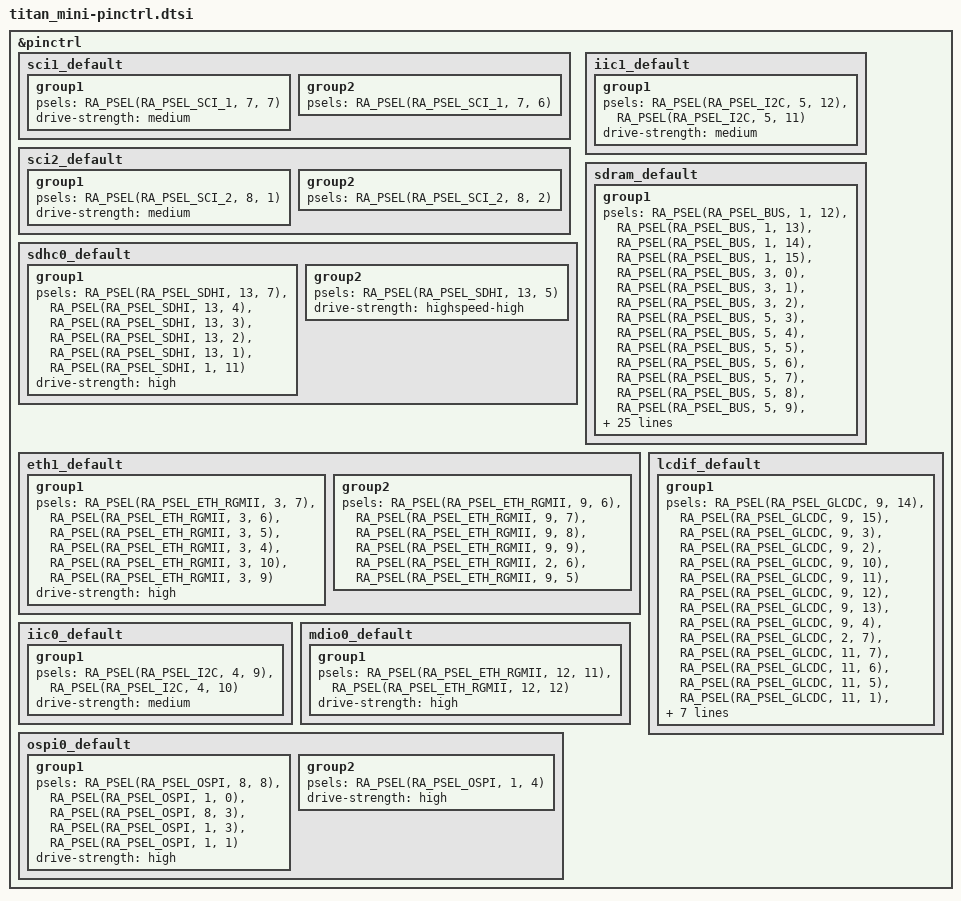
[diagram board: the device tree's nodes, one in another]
/*
 * Copyright (c) 2026 Titan Mini contributors
 * SPDX-License-Identifier: Apache-2.0
 *
 * Titan Mini board pinctrl (schematic: Titan_Mini HW V1.0)
 * Debug UART on U18 (RPi 40-pin): SCI1 TXD1 = P707, RXD1 = P706
 * Secondary UART on H1: SCI2 TXD2 = P801, RXD2 = P802
 */

#include <zephyr/dt-bindings/pinctrl/renesas/pinctrl-ra.h>

&pinctrl {
	sci1_default: sci1_default {
		group1 {
			/* tx */
			psels = <RA_PSEL(RA_PSEL_SCI_1, 7, 7)>;
			drive-strength = "medium";
		};

		group2 {
			/* rx */
			psels = <RA_PSEL(RA_PSEL_SCI_1, 7, 6)>;
		};
	};

	sci2_default: sci2_default {
		group1 {
			/* tx */
			psels = <RA_PSEL(RA_PSEL_SCI_2, 8, 1)>;
			drive-strength = "medium";
		};

		group2 {
			/* rx */
			psels = <RA_PSEL(RA_PSEL_SCI_2, 8, 2)>;
		};
	};

	sdhc0_default: sdhc0_default {
		group1 {
			psels = <RA_PSEL(RA_PSEL_SDHI, 13, 7)>, /* SDCD PD07 */
				<RA_PSEL(RA_PSEL_SDHI, 13, 4)>, /* SDCMD PD04 */
				<RA_PSEL(RA_PSEL_SDHI, 13, 3)>, /* SDDATA0 PD03 */
				<RA_PSEL(RA_PSEL_SDHI, 13, 2)>, /* SDDATA1 PD02 */
				<RA_PSEL(RA_PSEL_SDHI, 13, 1)>, /* SDDATA2 PD01 */
				<RA_PSEL(RA_PSEL_SDHI, 1, 11)>; /* SDDATA3 P111 */
			drive-strength = "high";
		};

		group2 {
			psels = <RA_PSEL(RA_PSEL_SDHI, 13, 5)>; /* SDCLK PD05 */
			drive-strength = "highspeed-high";
		};
	};

	iic1_default: iic1_default {
		group1 {
			/* SCL1 SDA1 (板上 10K 上拉, IMU 总线) */
			psels = <RA_PSEL(RA_PSEL_I2C, 5, 12)>,
				<RA_PSEL(RA_PSEL_I2C, 5, 11)>;
			drive-strength = "medium";
		};
	};

	sdram_default: sdram_default {
		group1 {
			/* SDRAM W9825G6KH-6 (32MB, 16-bit), 引脚集与官方 BSP pin_data 一致 */
			psels = <RA_PSEL(RA_PSEL_BUS, 1, 12)>, /* DQ3  P112 */
				<RA_PSEL(RA_PSEL_BUS, 1, 13)>, /* DQ4  P113 */
				<RA_PSEL(RA_PSEL_BUS, 1, 14)>, /* DQ5  P114 */
				<RA_PSEL(RA_PSEL_BUS, 1, 15)>, /* DQ6  P115 */
				<RA_PSEL(RA_PSEL_BUS, 3, 0)>, /* DQ2  P300 */
				<RA_PSEL(RA_PSEL_BUS, 3, 1)>, /* DQ1  P301 */
				<RA_PSEL(RA_PSEL_BUS, 3, 2)>, /* DQ0  P302 */
				<RA_PSEL(RA_PSEL_BUS, 5, 3)>, /* A5   P503 */
				<RA_PSEL(RA_PSEL_BUS, 5, 4)>, /* A6   P504 */
				<RA_PSEL(RA_PSEL_BUS, 5, 5)>, /* A7   P505 */
				<RA_PSEL(RA_PSEL_BUS, 5, 6)>, /* A8   P506 */
				<RA_PSEL(RA_PSEL_BUS, 5, 7)>, /* A9   P507 */
				<RA_PSEL(RA_PSEL_BUS, 5, 8)>, /* A10  P508 */
				<RA_PSEL(RA_PSEL_BUS, 5, 9)>, /* A11  P509 */
				<RA_PSEL(RA_PSEL_BUS, 5, 10)>, /* A12 P510 */
				<RA_PSEL(RA_PSEL_BUS, 6, 8)>, /* BA0  P608 */
				<RA_PSEL(RA_PSEL_BUS, 6, 9)>, /* DQ7  P609 */
				<RA_PSEL(RA_PSEL_BUS, 6, 10)>, /* DQ12 P610 */
				<RA_PSEL(RA_PSEL_BUS, 6, 11)>, /* DQ13 P611 */
				<RA_PSEL(RA_PSEL_BUS, 6, 12)>, /* DQ14 P612 */
				<RA_PSEL(RA_PSEL_BUS, 6, 13)>, /* DQ15 P613 */
				<RA_PSEL(RA_PSEL_BUS, 6, 14)>, /* DQM0 P614 */
				<RA_PSEL(RA_PSEL_BUS, 8, 13)>, /* SDCS P813 */
				<RA_PSEL(RA_PSEL_BUS, 10, 0)>, /* A4   PA00 */
				<RA_PSEL(RA_PSEL_BUS, 10, 1)>, /* A3   PA01 */
				<RA_PSEL(RA_PSEL_BUS, 10, 2)>, /* A2   PA02 */
				<RA_PSEL(RA_PSEL_BUS, 10, 3)>, /* A1   PA03 */
				<RA_PSEL(RA_PSEL_BUS, 10, 4)>, /* A0   PA04 */
				<RA_PSEL(RA_PSEL_BUS, 10, 5)>, /* DQM1 PA05 */
				<RA_PSEL(RA_PSEL_BUS, 10, 6)>, /* CKE  PA06 */
				<RA_PSEL(RA_PSEL_BUS, 10, 8)>, /* WE   PA08 */
				<RA_PSEL(RA_PSEL_BUS, 10, 9)>, /* CAS  PA09 */
				<RA_PSEL(RA_PSEL_BUS, 10, 10)>, /* RAS PA10 */
				<RA_PSEL(RA_PSEL_BUS, 10, 11)>, /* DQ8 PA11 */
				<RA_PSEL(RA_PSEL_BUS, 10, 12)>, /* DQ9 PA12 */
				<RA_PSEL(RA_PSEL_BUS, 10, 13)>, /* DQ10 PA13 */
				<RA_PSEL(RA_PSEL_BUS, 10, 14)>, /* DQ11 PA14 */
				<RA_PSEL(RA_PSEL_BUS, 10, 15)>, /* SDCLK PA15 */
				<RA_PSEL(RA_PSEL_BUS, 13, 0)>; /* BA1  PD00 */
		};
	};

	eth1_default: eth1_default {
		group1 {
			/* RGMII1_TXD0-3, TX_CTL, TXC */
			psels = <RA_PSEL(RA_PSEL_ETH_RGMII, 3, 7)>, /* TXD0 P307 */
				<RA_PSEL(RA_PSEL_ETH_RGMII, 3, 6)>, /* TXD1 P306 */
				<RA_PSEL(RA_PSEL_ETH_RGMII, 3, 5)>, /* TXD2 P305 */
				<RA_PSEL(RA_PSEL_ETH_RGMII, 3, 4)>, /* TXD3 P304 */
				<RA_PSEL(RA_PSEL_ETH_RGMII, 3, 10)>, /* TX_CTL P310 */
				<RA_PSEL(RA_PSEL_ETH_RGMII, 3, 9)>; /* TXC P309 */
			drive-strength = "high";
		};

		group2 {
			/* RGMII1_RXD0-3, RX_CTL, RXC */
			psels = <RA_PSEL(RA_PSEL_ETH_RGMII, 9, 6)>, /* RXD0 P906 */
				<RA_PSEL(RA_PSEL_ETH_RGMII, 9, 7)>, /* RXD1 P907 */
				<RA_PSEL(RA_PSEL_ETH_RGMII, 9, 8)>, /* RXD2 P908 */
				<RA_PSEL(RA_PSEL_ETH_RGMII, 9, 9)>, /* RXD3 P909 */
				<RA_PSEL(RA_PSEL_ETH_RGMII, 2, 6)>, /* RX_CTL P206 */
				<RA_PSEL(RA_PSEL_ETH_RGMII, 9, 5)>; /* RXC P905 */
		};
	};

	lcdif_default: lcdif_default {
		group1 {
			/* GLCDC RGB565: DATA0-15 (接 RGB888 屏高 16 位 R[7:3]G[7:2]B[7:3]) */
			psels = <RA_PSEL(RA_PSEL_GLCDC, 9, 14)>, /* DATA0  P914 */
				<RA_PSEL(RA_PSEL_GLCDC, 9, 15)>, /* DATA1  P915 */
				<RA_PSEL(RA_PSEL_GLCDC, 9, 3)>, /* DATA2  P903 */
				<RA_PSEL(RA_PSEL_GLCDC, 9, 2)>, /* DATA3  P902 */
				<RA_PSEL(RA_PSEL_GLCDC, 9, 10)>, /* DATA4 P910 */
				<RA_PSEL(RA_PSEL_GLCDC, 9, 11)>, /* DATA5 P911 */
				<RA_PSEL(RA_PSEL_GLCDC, 9, 12)>, /* DATA6 P912 */
				<RA_PSEL(RA_PSEL_GLCDC, 9, 13)>, /* DATA7 P913 */
				<RA_PSEL(RA_PSEL_GLCDC, 9, 4)>, /* DATA8  P904 */
				<RA_PSEL(RA_PSEL_GLCDC, 2, 7)>, /* DATA9  P207 */
				<RA_PSEL(RA_PSEL_GLCDC, 11, 7)>, /* DATA10 PB07 */
				<RA_PSEL(RA_PSEL_GLCDC, 11, 6)>, /* DATA11 PB06 */
				<RA_PSEL(RA_PSEL_GLCDC, 11, 5)>, /* DATA12 PB05 */
				<RA_PSEL(RA_PSEL_GLCDC, 11, 1)>, /* DATA13 PB01 */
				<RA_PSEL(RA_PSEL_GLCDC, 11, 4)>, /* DATA14 PB04 */
				<RA_PSEL(RA_PSEL_GLCDC, 11, 3)>, /* DATA15 PB03 */
				<RA_PSEL(RA_PSEL_GLCDC, 5, 15)>, /* CLK   P515 */
				<RA_PSEL(RA_PSEL_GLCDC, 8, 6)>, /* TCON0(HSYNC) P806 */
				<RA_PSEL(RA_PSEL_GLCDC, 8, 5)>, /* TCON1(VSYNC) P805 */
				<RA_PSEL(RA_PSEL_GLCDC, 5, 13)>; /* TCON3(DE)     P513 */
			drive-strength = "high";
		};
	};

	iic0_default: iic0_default {
		group1 {
			/* SDA0 P409, SCL0 P410 (触摸 GT911 总线, 板上 10K 上拉) */
			psels = <RA_PSEL(RA_PSEL_I2C, 4, 9)>,
				<RA_PSEL(RA_PSEL_I2C, 4, 10)>;
			drive-strength = "medium";
		};
	};

	mdio0_default: mdio0_default {
		group1 {
			/* MDC ET0_MDC PC11, MDIO ET0_MDIO PC12 (板子 MDIO 走通道 0);
			 * 官方 BSP 在这两个脚上用 ETHER_RGMII(0x18) 复用, 不是 ETH_MII */
			psels = <RA_PSEL(RA_PSEL_ETH_RGMII, 12, 11)>,
				<RA_PSEL(RA_PSEL_ETH_RGMII, 12, 12)>;
			drive-strength = "high";
		};
	};

	ospi0_default: ospi0_default {
		group1 {
			/* sclk sio0-3 (W25Q64JVSSIQ, quad) */
			psels = <RA_PSEL(RA_PSEL_OSPI, 8, 8)>, /* OM_0_SCLK P808 */
				<RA_PSEL(RA_PSEL_OSPI, 1, 0)>, /* OM_0_SIO0 P100 */
				<RA_PSEL(RA_PSEL_OSPI, 8, 3)>, /* OM_0_SIO1 P803 */
				<RA_PSEL(RA_PSEL_OSPI, 1, 3)>, /* OM_0_SIO2 P103 */
				<RA_PSEL(RA_PSEL_OSPI, 1, 1)>; /* OM_0_SIO3 P101 */
			drive-strength = "high";
		};

		group2 {
			/* cs1 */
			psels = <RA_PSEL(RA_PSEL_OSPI, 1, 4)>; /* OM_0_CS1 P104 */
			drive-strength = "high";
		};
	};
};
